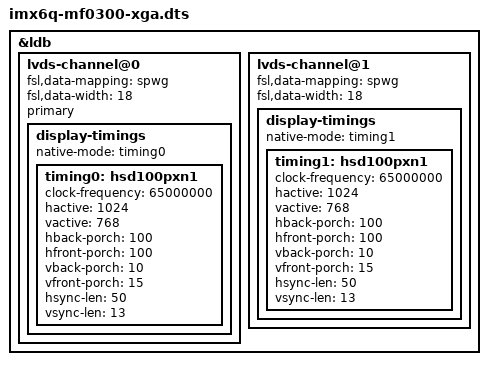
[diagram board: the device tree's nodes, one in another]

/*
 * Copyright 2012-2013 Freescale Semiconductor, Inc.
 * Copyright 2011 Linaro Ltd.
 *
 * The code contained herein is licensed under the GNU General Public
 * License. You may obtain a copy of the GNU General Public License
 * Version 2 or later at the following locations:
 *
 * http://www.opensource.org/licenses/gpl-license.html
 * http://www.gnu.org/copyleft/gpl.html
 */

#include "imx6q-mf0300.dts"

&ldb {
	status = "okay";

	lvds-channel@0 {
		fsl,data-mapping = "spwg";
		fsl,data-width = <18>;
		primary;
		status = "okay";

		display-timings {
			native-mode = <&timing0>;
			timing0: hsd100pxn1 {
				clock-frequency = <65000000>;
				hactive = <1024>;
				vactive = <768>;
				hback-porch = <100>;
				hfront-porch = <100>;
				vback-porch = <10>;
				vfront-porch = <15>;
				hsync-len = <50>;
				vsync-len = <13>;
			};
		};
	};

	lvds-channel@1 {
		fsl,data-mapping = "spwg";
		fsl,data-width = <18>;
		status = "okay";

		display-timings {
			native-mode = <&timing1>;
			timing1: hsd100pxn1 {
				clock-frequency = <65000000>;
				hactive = <1024>;
				vactive = <768>;
				hback-porch = <100>;
				hfront-porch = <100>;
				vback-porch = <10>;
				vfront-porch = <15>;
				hsync-len = <50>;
				vsync-len = <13>;
			};
		};
	};
};
